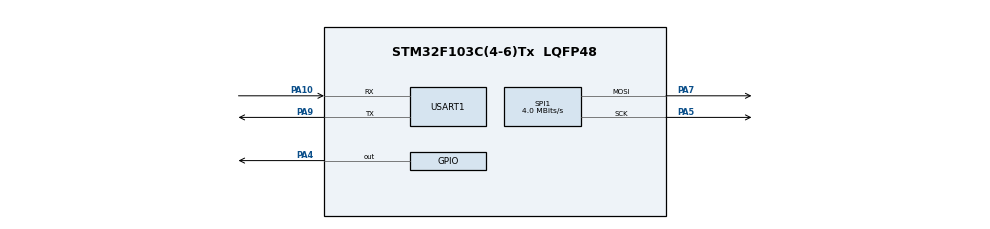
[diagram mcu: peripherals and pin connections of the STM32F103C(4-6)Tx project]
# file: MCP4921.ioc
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Mcu.Family=STM32F1
Mcu.Name=STM32F103C(4-6)Tx
Mcu.Package=LQFP48
NVIC.PriorityGroup=NVIC_PRIORITYGROUP_4
PA10.Mode=Asynchronous
PA10.Signal=USART1_RX
PA4.Signal=GPIO_Output
PA5.Mode=TX_Only_Simplex_Unidirect_Master
PA5.Signal=SPI1_SCK
PA7.Mode=TX_Only_Simplex_Unidirect_Master
PA7.Signal=SPI1_MOSI
PA9.Mode=Asynchronous
PA9.Signal=USART1_TX
ProjectManager.HeapSize=0x200
ProjectManager.StackSize=0x400
ProjectManager.TargetToolchain=STM32CubeIDE
RCC.APB1Freq_Value=8000000
RCC.APB2Freq_Value=8000000
SPI1.BaudRatePrescaler=SPI_BAUDRATEPRESCALER_2
SPI1.CalculateBaudRate=4.0 MBits/s
SPI1.Direction=SPI_DIRECTION_2LINES
SPI1.Mode=SPI_MODE_MASTER
SPI1.VirtualType=VM_MASTER
USART1.VirtualMode=VM_ASYNC
VP_SYS_VS_ND.Mode=No_Debug
board=custom

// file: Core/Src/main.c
/* USER CODE BEGIN Header */
/**
  ******************************************************************************
  * @file           : main.c
  * @brief          : Main program body
  ******************************************************************************
  * @attention
  *
  * Copyright (c) 2024 STMicroelectronics.
  * All rights reserved.
  *
  * This software is licensed under terms that can be found in the LICENSE file
  * in the root directory of this software component.
  * If no LICENSE file comes with this software, it is provided AS-IS.
  *
  ******************************************************************************
  */
/* USER CODE END Header */
#include "main.h"

/* USER CODE BEGIN Includes */
#include "MCP492X.h"        // Include the MCP492X header

/* USER CODE END Includes */

SPI_HandleTypeDef hspi1;

UART_HandleTypeDef huart1;

/* USER CODE BEGIN PV */
DAC_MCP49x1_HandleTypeDef hdac;

#define CS_ADC_PIN GPIO_PIN_4
#define CS_ADC_PORT GPIOA
#define CS_DAC_PIN GPIO_PIN_9
#define CS_DAC_PORT GPIOA
/* USER CODE END PV */

void SystemClock_Config(void);
static void MX_GPIO_Init(void);
static void MX_SPI1_Init(void);
static void MX_USART1_UART_Init(void);

/* USER CODE BEGIN 0 */
/*int Read3202(int CHANNEL, uint16_t CS_PIN, GPIO_TypeDef *CS_PORT)
{
    uint8_t msb;
    uint8_t lsb;
    uint8_t commandBytes = 0xA0;  // Channel 0 command

    if (CHANNEL == 1)
        commandBytes = 0xE0;  // Channel 1 command

    HAL_GPIO_WritePin(CS_PORT, CS_PIN, GPIO_PIN_RESET); // CS LOW

    uint8_t startByte = 0x01;
    HAL_SPI_Transmit(&hspi1, &startByte, 1, HAL_MAX_DELAY);  // Start bit
    HAL_SPI_TransmitReceive(&hspi1, &commandBytes, &msb, 1, HAL_MAX_DELAY);  // Command and MSB
    msb &= 0x0F;
    uint8_t dummy = 0x00;
    HAL_SPI_TransmitReceive(&hspi1, &dummy, &lsb, 1, HAL_MAX_DELAY);  // LSB

    HAL_GPIO_WritePin(CS_PORT, CS_PIN, GPIO_PIN_SET); // CS HIGH

    return ((int)msb << 8) | lsb;
}

void Write4921(int value, uint16_t CS_PIN, GPIO_TypeDef *CS_PORT)
{
    uint8_t data;

    HAL_GPIO_WritePin(CS_PORT, CS_PIN, GPIO_PIN_RESET); // CS LOW

    data = (value >> 8) & 0x0F;
    data |= 0x30;
    HAL_SPI_Transmit(&hspi1, &data, 1, HAL_MAX_DELAY);

    data = value & 0xFF;
    HAL_SPI_Transmit(&hspi1, &data, 1, HAL_MAX_DELAY);

    HAL_GPIO_WritePin(CS_PORT, CS_PIN, GPIO_PIN_SET); // CS HIGH
}*/
/* USER CODE END 0 */

int main(void)
{

  /* MCU Configuration--------------------------------------------------------*/

  /* Reset of all peripherals, Initializes the Flash interface and the Systick. */
  HAL_Init();

  /* Configure the system clock */
  SystemClock_Config();

  /* Initialize all configured peripherals */
  MX_GPIO_Init();
  MX_SPI1_Init();
  MX_USART1_UART_Init();
  /* USER CODE BEGIN 2 */
  // Initialize the MCP492X
  DAC_MCP49x1_Init(&hdac, MCP4921, &hspi1, GPIOA, GPIO_PIN_4, NULL, 0);
  int analogValue;

  /* USER CODE END 2 */

  /* Infinite loop */
  while (1)
  {

    /* USER CODE BEGIN 3 */
	DAC_MCP49x1_Output(&hdac, 0);
	HAL_Delay(100);
	DAC_MCP49x1_Output(&hdac, 4095);
	HAL_Delay(100);
	  //analogValue = Read3202(0, CS_ADC_PIN, CS_ADC_PORT);
	   //       Write4921(analogValue, CS_ADC_PIN, CS_ADC_PORT);
  }
  /* USER CODE END 3 */
}

void SystemClock_Config(void)
{
  RCC_OscInitTypeDef RCC_OscInitStruct = {0};
  RCC_ClkInitTypeDef RCC_ClkInitStruct = {0};

  /** Initializes the RCC Oscillators according to the specified parameters
  * in the RCC_OscInitTypeDef structure.
  */
  RCC_OscInitStruct.OscillatorType = RCC_OSCILLATORTYPE_HSI;
  RCC_OscInitStruct.HSIState = RCC_HSI_ON;
  RCC_OscInitStruct.HSICalibrationValue = RCC_HSICALIBRATION_DEFAULT;
  RCC_OscInitStruct.PLL.PLLState = RCC_PLL_NONE;
  if (HAL_RCC_OscConfig(&RCC_OscInitStruct) != HAL_OK)
  {
    Error_Handler();
  }

  /** Initializes the CPU, AHB and APB buses clocks
  */
  RCC_ClkInitStruct.ClockType = RCC_CLOCKTYPE_HCLK|RCC_CLOCKTYPE_SYSCLK
                              |RCC_CLOCKTYPE_PCLK1|RCC_CLOCKTYPE_PCLK2;
  RCC_ClkInitStruct.SYSCLKSource = RCC_SYSCLKSOURCE_HSI;
  RCC_ClkInitStruct.AHBCLKDivider = RCC_SYSCLK_DIV1;
  RCC_ClkInitStruct.APB1CLKDivider = RCC_HCLK_DIV1;
  RCC_ClkInitStruct.APB2CLKDivider = RCC_HCLK_DIV1;

  if (HAL_RCC_ClockConfig(&RCC_ClkInitStruct, FLASH_LATENCY_0) != HAL_OK)
  {
    Error_Handler();
  }
}

static void MX_SPI1_Init(void)
{

  /* SPI1 parameter configuration*/
  hspi1.Instance = SPI1;
  hspi1.Init.Mode = SPI_MODE_MASTER;
  hspi1.Init.Direction = SPI_DIRECTION_2LINES;
  hspi1.Init.DataSize = SPI_DATASIZE_8BIT;
  hspi1.Init.CLKPolarity = SPI_POLARITY_LOW;
  hspi1.Init.CLKPhase = SPI_PHASE_1EDGE;
  hspi1.Init.NSS = SPI_NSS_SOFT;
  hspi1.Init.BaudRatePrescaler = SPI_BAUDRATEPRESCALER_2;
  hspi1.Init.FirstBit = SPI_FIRSTBIT_MSB;
  hspi1.Init.TIMode = SPI_TIMODE_DISABLE;
  hspi1.Init.CRCCalculation = SPI_CRCCALCULATION_DISABLE;
  hspi1.Init.CRCPolynomial = 10;
  if (HAL_SPI_Init(&hspi1) != HAL_OK)
  {
    Error_Handler();
  }

}

static void MX_USART1_UART_Init(void)
{

  huart1.Instance = USART1;
  huart1.Init.BaudRate = 115200;
  huart1.Init.WordLength = UART_WORDLENGTH_8B;
  huart1.Init.StopBits = UART_STOPBITS_1;
  huart1.Init.Parity = UART_PARITY_NONE;
  huart1.Init.Mode = UART_MODE_TX_RX;
  huart1.Init.HwFlowCtl = UART_HWCONTROL_NONE;
  huart1.Init.OverSampling = UART_OVERSAMPLING_16;
  if (HAL_UART_Init(&huart1) != HAL_OK)
  {
    Error_Handler();
  }

}

static void MX_GPIO_Init(void)
{
  GPIO_InitTypeDef GPIO_InitStruct = {0};

  /* GPIO Ports Clock Enable */
  __HAL_RCC_GPIOA_CLK_ENABLE();

  /*Configure GPIO pin Output Level */
  HAL_GPIO_WritePin(GPIOA, GPIO_PIN_4, GPIO_PIN_RESET);

  /*Configure GPIO pin : PA4 */
  GPIO_InitStruct.Pin = GPIO_PIN_4;
  GPIO_InitStruct.Mode = GPIO_MODE_OUTPUT_PP;
  GPIO_InitStruct.Pull = GPIO_NOPULL;
  GPIO_InitStruct.Speed = GPIO_SPEED_FREQ_LOW;
  HAL_GPIO_Init(GPIOA, &GPIO_InitStruct);

}

void Error_Handler(void)
{
  __disable_irq();
  while (1)
  {
  }
}
